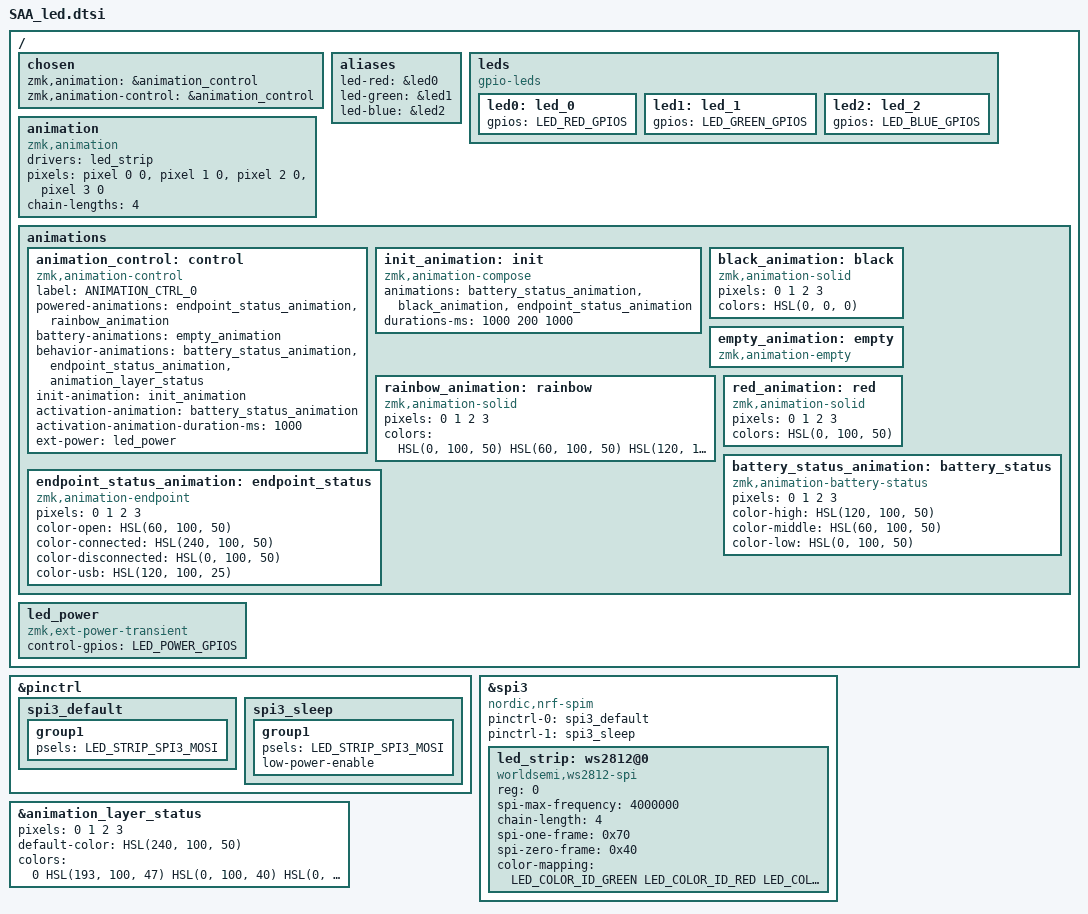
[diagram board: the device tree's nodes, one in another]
#include <behaviors/animation_trigger.dtsi>
#include <behaviors/animation_control.dtsi>
#include <dt-bindings/led/led.h>
#include <dt-bindings/zmk_driver_animation/animation_control.h>
#include <dt-bindings/zmk_driver_animation/animation_trigger.h>
#include <zmk_driver_animation/animation.dtsi>
#include <zmk_driver_animation/animation_layer_status.dtsi>
#include <behaviors/rgbled_widget.dtsi>

/ {
	chosen {
		zmk,animation = &animation_control;
		zmk,animation-control = &animation_control;
	};

	aliases {
		led-red = &led0;
		led-green = &led1;
		led-blue = &led2;
	};

	leds {
		compatible = "gpio-leds";
		status = "okay";

		led0: led_0 {
			gpios = LED_RED_GPIOS;
		};

		led1: led_1 {
			gpios = LED_GREEN_GPIOS;
		};

		led2: led_2 {
			gpios = LED_BLUE_GPIOS;
		};
	};


	animation: animation {
		compatible = "zmk,animation";
		drivers = <&led_strip>;
		pixels = <&pixel 0 0>,
		<&pixel 1 0>,
		<&pixel 2 0>,
		<&pixel 3 0>;
		chain-lengths = <4>;
	};
	
	animations {
		/omit-if-no-ref/ animation_control: control {
			compatible = "zmk,animation-control";
			label = "ANIMATION_CTRL_0";
			powered-animations = <&endpoint_status_animation &rainbow_animation>;
			battery-animations = <&empty_animation>;
			behavior-animations = <&battery_status_animation &endpoint_status_animation &animation_layer_status>;
			init-animation = <&init_animation>;
			activation-animation = <&battery_status_animation>;
			activation-animation-duration-ms = <1000>;
			ext-power = <&led_power>;
		};
		/omit-if-no-ref/ init_animation: init {
			compatible = "zmk,animation-compose";
			animations = <&battery_status_animation &black_animation &endpoint_status_animation>;
			durations-ms = <1000 200 1000>;
		};
		/omit-if-no-ref/ black_animation: black {
			compatible = "zmk,animation-solid";
			pixels = <0 1 2 3>;
			colors = <HSL(0, 0, 0)>;
		};
		
		/omit-if-no-ref/ empty_animation: empty {
			compatible = "zmk,animation-empty";
			status = "okay";
		};
		/omit-if-no-ref/ rainbow_animation: rainbow {
			compatible = "zmk,animation-solid";
			status = "okay";
			pixels = <0 1 2 3>;
			colors = <HSL(0, 100, 50) HSL(60, 100, 50) HSL(120, 100, 50) HSL(180, 100, 50) HSL(240, 100, 50) HSL(300, 100, 50)>;
		};
		/omit-if-no-ref/ red_animation: red {
			compatible = "zmk,animation-solid";
			status = "okay";
			pixels = <0 1 2 3>;
			colors = <HSL(0, 100, 50)>;
		};
		/omit-if-no-ref/ endpoint_status_animation: endpoint_status {
			compatible = "zmk,animation-endpoint";
			status = "okay";
			pixels = <0 1 2 3>;
			color-open = <HSL(60, 100, 50)>;
			color-connected = <HSL(240, 100, 50)>;
			color-disconnected = <HSL(0, 100, 50)>;
			color-usb = <HSL(120, 100, 25)>;
		};
		/omit-if-no-ref/ battery_status_animation: battery_status {
			compatible = "zmk,animation-battery-status";
			status = "okay";
			pixels = <0 1 2 3>;
			color-high = <HSL(120, 100, 50)>;// green
			color-middle = <HSL(60, 100, 50)>;// yellow
			color-low = <HSL(0, 100, 50)>;// red
		};
	};
   
	led_power:led_power {
		compatible = "zmk,ext-power-transient";
		control-gpios = LED_POWER_GPIOS;
	};
};

//
// pinctrl for LED strip (WS2812 2020)
//

&pinctrl {
	spi3_default: spi3_default {
		group1 {
			psels = <LED_STRIP_SPI3_MOSI>;
		};
	};
	
	spi3_sleep: spi3_sleep {
		group1 {
			psels = <LED_STRIP_SPI3_MOSI>;
			low-power-enable;
		};
	};
};

&spi3 {
	compatible = "nordic,nrf-spim";
	status = "okay";

	pinctrl-0 = <&spi3_default>;
	pinctrl-1 = <&spi3_sleep>;
	pinctrl-names = "default", "sleep";

	led_strip: ws2812@0 {
		compatible = "worldsemi,ws2812-spi";
		reg = <0>;
		spi-max-frequency = <4000000>; // 4MHz = 0.25us

		chain-length = <4>; /* number of LEDs */
		spi-one-frame = <0x70>; // 01110000 -> T1H = 0.25 * 3 = 0.75us
		spi-zero-frame = <0x40>; // 01000000 -> T0H = 0.25us
		color-mapping = <LED_COLOR_ID_GREEN
				 LED_COLOR_ID_RED
				 LED_COLOR_ID_BLUE>;
	};
};

&animation_layer_status {
	pixels = <0 1 2 3>;
	default-color = <HSL(240, 100, 50)>;
	// default
	// windows blue
	// mac red
	// ios white
	// linux orange
	colors = <
		0
		HSL(193, 100, 47)
		HSL(0, 100, 40)
		HSL(0, 100, 100)
		HSL(29, 88, 51)
	>;
};
